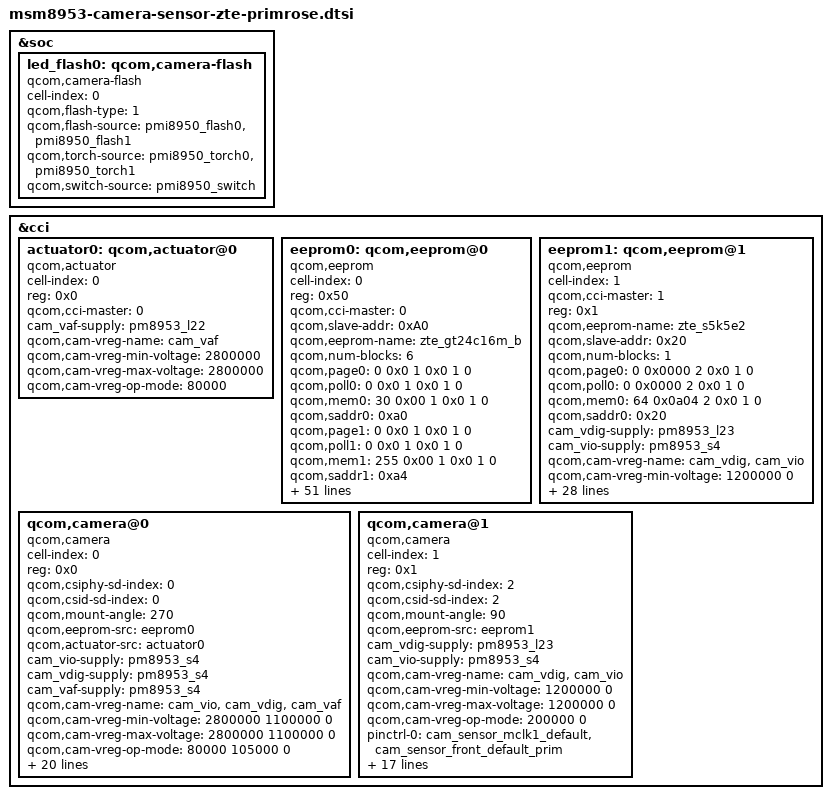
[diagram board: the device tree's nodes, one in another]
/*
 * Copyright (c) 2015-2016, The Linux Foundation. All rights reserved.
 *
 * This program is free software; you can redistribute it and/or modify
 * it under the terms of the GNU General Public License version 2 and
 * only version 2 as published by the Free Software Foundation.
 *
 * This program is distributed in the hope that it will be useful,
 * but WITHOUT ANY WARRANTY; without even the implied warranty of
 * MERCHANTABILITY or FITNESS FOR A PARTICULAR PURPOSE.  See the
 * GNU General Public License for more details.
 */

&soc {
	led_flash0: qcom,camera-flash {
		cell-index = <0>;
		compatible = "qcom,camera-flash";
		qcom,flash-type = <1>;
		qcom,flash-source = <&pmi8950_flash0 &pmi8950_flash1>;
		qcom,torch-source = <&pmi8950_torch0 &pmi8950_torch1>;
		qcom,switch-source = <&pmi8950_switch>;
	};
};

&cci {
	actuator0: qcom,actuator@0 {
		cell-index = <0>;
		reg = <0x0>;
		compatible = "qcom,actuator";
		qcom,cci-master = <0>;
		cam_vaf-supply = <&pm8953_l22>;
		qcom,cam-vreg-name = "cam_vaf";
		qcom,cam-vreg-min-voltage = <2800000>;
		qcom,cam-vreg-max-voltage = <2800000>;
		qcom,cam-vreg-op-mode = <80000>;
	};


	eeprom0: qcom,eeprom@0 {
		   cell-index = <0>;
		   reg = <0x50>;  //must be 7bit addr
		   compatible = "qcom,eeprom";
		   qcom,cci-master = <0>;
		   qcom,slave-addr = <0xA0>;  //8bit addr
		   qcom,eeprom-name = "zte_gt24c16m_b";
		   qcom,num-blocks = <6>;
		   qcom,page0 = <0 0x0 1 0x0 1 0>;
		   qcom,poll0 = <0 0x0 1 0x0 1 0>;
		   qcom,mem0 = <30 0x00 1 0x0 1 0>;  //module info,AWB,AF and others
		   qcom,saddr0 =<0xa0>;//8bit addr
		   qcom,page1 = <0 0x0 1 0x0 1 0>;
		   qcom,poll1 = <0 0x0 1 0x0 1 0>;
		   qcom,mem1 = <255 0x00 1 0x0 1 0>;  //LSC(ROI1-ROI51,R,Gr,Gb,B)
		   qcom,saddr1 =<0xa4>;
		   qcom,page2 = <0 0x0 1 0x0 1 0>;
		   qcom,poll2 = <0 0x0 1 0x0 1 0>;
		   qcom,mem2 = <255 0x00 1 0x0 1 0>;  //LSC(ROI52-ROI102,R,Gr,Gb,B)
		   qcom,saddr2 =<0xa6>;
		   qcom,page3 = <0 0x0 1 0x0 1 0>;
		   qcom,poll3 = <0 0x0 1 0x0 1 0>;
		   qcom,mem3 = <255 0x00 1 0x0 1 0>;  //LSC(ROI103-ROI153,R,Gr,Gb,B)
		   qcom,saddr3 =<0xa8>;
		   qcom,page4 = <0 0x0 1 0x0 1 0>;
		   qcom,poll4 = <0 0x0 1 0x0 1 0>;
		   qcom,mem4 = <255 0x00 1 0x0 1 0>;  //LSC(ROI154-ROI204,R,Gr,Gb,B)
		   qcom,saddr4 =<0xaa>;
		   qcom,page5 = <0 0x0 1 0x0 1 0>;
		   qcom,poll5 = <0 0x0 1 0x0 1 0>;
		   qcom,mem5 = <85 0x00 1 0x0 1 0>;  //LSC(ROI205-ROI221,R,Gr,Gb,B)
		   qcom,saddr5 =<0xac>;
		cam_vio-supply = <&pm8953_s4>;
		cam_vdig-supply = <&pm8953_s4>;
		cam_vaf-supply = <&pm8953_s4>;
		qcom,cam-vreg-name = "cam_vio", "cam_vdig","cam_vaf" ;
		qcom,cam-vreg-min-voltage = <2800000 1100000 0>;
		qcom,cam-vreg-max-voltage = <2800000 1100000 0>;
		qcom,cam-vreg-op-mode = <80000 105000 0>;
		pinctrl-names = "cam_default", "cam_suspend";
		pinctrl-0 = <&cam_sensor_mclk0_default
				&cam_sensor_rear_default_prim>;
		pinctrl-1 = <&cam_sensor_mclk0_sleep &cam_sensor_rear_sleep_prim>;
		gpios = <&tlmm 26 0>,
			<&tlmm 9 0>,
			<&tlmm 44 0>,
			<&tlmm 35 0>,
			<&tlmm 36 0>;
		qcom,gpio-reset = <1>;
		qcom,gpio-vio = <2>;
		qcom,gpio-vana = <3>;
		qcom,gpio-vdig = <4>;
		qcom,gpio-req-tbl-num = <0 1 2 3 4>;
		qcom,gpio-req-tbl-flags = <1 0 0 0 0>;
		qcom,gpio-req-tbl-label = "CAMIF_MCLK0",
			"CAM_RESET0",
			"CAM_IO",
			"CAM_AVDD",
			"CAM_DVDD";
		   qcom,cam-power-seq-type = "sensor_gpio","sensor_gpio","sensor_gpio","sensor_gpio","sensor_gpio",
			   "sensor_gpio", "sensor_gpio",
			   "sensor_clk";
		   qcom,cam-power-seq-val = "sensor_gpio_vio",
						   "sensor_gpio_vdig",
						   "sensor_gpio_vana",
						   "sensor_gpio_standby",
						   "sensor_gpio_standby",
						   "sensor_gpio_reset",
						   "sensor_gpio_reset",
						   "sensor_cam_mclk" ;
		   qcom,cam-power-seq-cfg-val = <1 1 1 0 1 0 1 24000000>;
		   qcom,cam-power-seq-delay = <1 1 1 1 10 10 1 5>;
		   clocks = <&clock_gcc clk_mclk0_clk_src>,
			   <&clock_gcc clk_gcc_camss_mclk0_clk>;
		   clock-names = "cam_src_clk", "cam_clk";
	   };


	eeprom1: qcom,eeprom@1 {
		cell-index = <1>;
		compatible = "qcom,eeprom";
		qcom,cci-master = <1>;
		reg = <0x1>;
		qcom,eeprom-name = "zte_s5k5e2";
		qcom,slave-addr = <0x20>;
		qcom,num-blocks = <1>;
		qcom,page0 = <0 0x0000 2 0x0 1 0>;
		qcom,poll0 = <0 0x0000 2 0x0 1 0>;
		qcom,mem0  = <64 0x0a04 2 0x0 1 0>;
		qcom,saddr0 = <0x20>;
		cam_vdig-supply = <&pm8953_l23>;
		cam_vio-supply = <&pm8953_s4>;
		qcom,cam-vreg-name = "cam_vdig", "cam_vio";
		qcom,cam-vreg-min-voltage = <1200000 0>;
		qcom,cam-vreg-max-voltage = <1200000 0>;
		qcom,cam-vreg-op-mode = <200000 0>;
		pinctrl-names = "cam_default", "cam_suspend";
		pinctrl-0 = <&cam_sensor_mclk1_default
				&cam_sensor_front_default_prim>;
		pinctrl-1 = <&cam_sensor_mclk1_sleep
				&cam_sensor_front_sleep_prim>;
		gpios = <&tlmm 27 0>,
			<&pm8953_gpios 6 0>,
			<&tlmm 44 0>,
			<&tlmm 8 0>;
		qcom,gpio-reset = <1>;
		qcom,gpio-vio = <2>;
		qcom,gpio-vana = <3>;
		qcom,gpio-req-tbl-num = <0 1 2 3>;
		qcom,gpio-req-tbl-flags = <1 0 0 0>;
		qcom,gpio-req-tbl-label = "CAMIF_MCLK1",
			"CAM_RESET1",
			"CAM_IO1",
			"CAM_AVDD1";
		qcom,cam-power-seq-type = "sensor_gpio", "sensor_gpio", "sensor_gpio",
			"sensor_vreg", "sensor_gpio", "sensor_gpio","sensor_clk";
		qcom,cam-power-seq-val ="sensor_gpio_reset","sensor_gpio_vana",
			"sensor_gpio_vio", "cam_vdig", "sensor_gpio_vio", "sensor_gpio_reset", "sensor_cam_mclk";
		qcom,cam-power-seq-cfg-val = <0 1 1 0 1 1 24000000>;
		qcom,cam-power-seq-delay = <1 1 1 0  0 0 1 12>;
		status = "ok";
		clocks = <&clock_gcc clk_mclk1_clk_src>,
				<&clock_gcc clk_gcc_camss_mclk1_clk>;
		clock-names = "cam_src_clk", "cam_clk";
		qcom,clock-rates = <24000000 0>;
	};


	qcom,camera@0 {
		cell-index = <0>;
		compatible = "qcom,camera";
		reg = <0x0>;
		qcom,csiphy-sd-index = <0>;
		qcom,csid-sd-index = <0>;
		qcom,mount-angle = <270>;
		qcom,eeprom-src = <&eeprom0>;
		qcom,actuator-src = <&actuator0>;
		cam_vio-supply = <&pm8953_s4>;
		cam_vdig-supply = <&pm8953_s4>;
		cam_vaf-supply = <&pm8953_s4>;
		qcom,cam-vreg-name = "cam_vio", "cam_vdig","cam_vaf" ;
		qcom,cam-vreg-min-voltage = <2800000 1100000 0>;
		qcom,cam-vreg-max-voltage = <2800000 1100000 0>;
		qcom,cam-vreg-op-mode = <80000 105000 0>;
		pinctrl-names = "cam_default", "cam_suspend";
		pinctrl-0 = <&cam_sensor_mclk0_default
				&cam_sensor_rear_default_prim>;
		pinctrl-1 = <&cam_sensor_mclk0_sleep &cam_sensor_rear_sleep_prim>;
		gpios = <&tlmm 26 0>,
			<&tlmm 9 0>,
			<&tlmm 44 0>,
			<&tlmm 35 0>,
			<&tlmm 36 0>;
		qcom,gpio-reset = <1>;
		qcom,gpio-vio = <2>;
		qcom,gpio-vana = <3>;
		qcom,gpio-vdig = <4>;
		qcom,gpio-req-tbl-num = <0 1 2 3 4>;
		qcom,gpio-req-tbl-flags = <1 0 0 0 0>;
		qcom,gpio-req-tbl-label = "CAMIF_MCLK0",
			"CAM_RESET0",
			"CAM_IO",
			"CAM_AVDD",
			"CAM_DVDD";
		qcom,sensor-position = <0>;
		qcom,sensor-mode = <0>;
		qcom,cci-master = <0>;
		status = "ok";
		clocks = <&clock_gcc clk_mclk0_clk_src>,
				<&clock_gcc clk_gcc_camss_mclk0_clk>;
		clock-names = "cam_src_clk", "cam_clk";
		qcom,clock-rates = <24000000 0>;
	};

	qcom,camera@1 {
		cell-index = <1>;
		compatible = "qcom,camera";
		reg = <0x1>;
		qcom,csiphy-sd-index = <2>;
		qcom,csid-sd-index = <2>;
		qcom,mount-angle = <90>;
		qcom,eeprom-src = <&eeprom1>;
		cam_vdig-supply = <&pm8953_l23>;
		cam_vio-supply = <&pm8953_s4>;
		qcom,cam-vreg-name = "cam_vdig", "cam_vio";
		qcom,cam-vreg-min-voltage = <1200000 0>;
		qcom,cam-vreg-max-voltage = <1200000 0>;
		qcom,cam-vreg-op-mode = <200000 0>;
		pinctrl-names = "cam_default", "cam_suspend";
		pinctrl-0 = <&cam_sensor_mclk1_default
				&cam_sensor_front_default_prim>;
		pinctrl-1 = <&cam_sensor_mclk1_sleep
				&cam_sensor_front_sleep_prim>;
		gpios = <&tlmm 27 0>,
			<&pm8953_gpios 6 0>,
			<&tlmm 44 0>,
			<&tlmm 8 0>;
		qcom,gpio-reset = <1>;
		qcom,gpio-vio = <2>;
		qcom,gpio-vana = <3>;
		qcom,gpio-req-tbl-num = <0 1 2 3>;
		qcom,gpio-req-tbl-flags = <1 0 0 0>;
		qcom,gpio-req-tbl-label = "CAMIF_MCLK1",
			"CAM_RESET1",
			"CAM_IO1",
			"CAM_AVDD1";
		qcom,sensor-position = <1>;
		qcom,sensor-mode = <0>;
		qcom,cci-master = <1>;
		status = "ok";
		clocks = <&clock_gcc clk_mclk1_clk_src>,
				<&clock_gcc clk_gcc_camss_mclk1_clk>;
		clock-names = "cam_src_clk", "cam_clk";
		qcom,clock-rates = <24000000 0>;
	};
};
